# STM32G473 register map
File version: 2.2
CPU: CM4 r0p1, little endian, MPU, FPU, 4 interrupt priority bits
Registers are 32-bit, read-write, reset 0x0 unless marked. A register's access mark holds for its fields unless they carry their own. Offsets are from the block's base; [hi:lo] are bit positions; {n}, {i} and the like mark numbered series; 'fields as' and 'values as' point back to an identical list.

## TIM6 — Basic-timers
Base 0x40001000
Same registers: TIM7 0x40001400
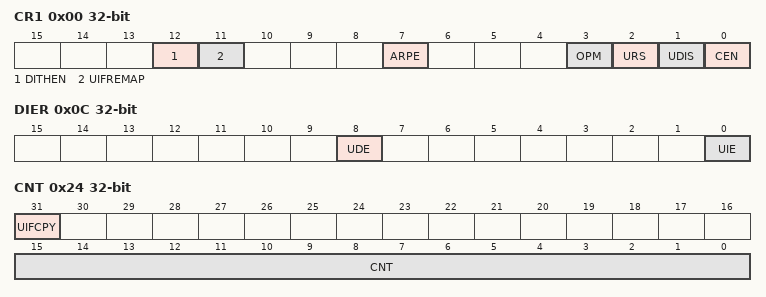
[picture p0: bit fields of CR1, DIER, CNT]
0x00 CR1 — control register 1
  [12] DITHEN — Dithering Enable
    0=Disabled (Dithering disabled); 1=Enabled (Dithering enabled)
  [11] UIFREMAP — UIF status bit remapping
    0=Disabled (No remapping. UIF status bit is not copied to TIMx_CNT register bit 31); 1=Enabled (Remapping enabled. UIF status bit is copied to TIMx_CNT register bit 31)
  [7] ARPE — Auto-reload preload enable
    0=Disabled (TIMx_APRR register is not buffered); 1=Enabled (TIMx_APRR register is buffered)
  [3] OPM — One-pulse mode
    0=Disabled (Counter is not stopped at update event); 1=Enabled (Counter stops counting at the next update event (clearing the CEN bit))
  [2] URS — Update request source
    0=AnyEvent (Any of counter overflow/underflow, setting UG, or update through slave mode, generates an update interrupt or DMA request); 1=CounterOnly (Only counter overflow/underflow generates an update interrupt or DMA request)
  [1] UDIS — Update disable
    0=Enabled (Update event enabled); 1=Disabled (Update event disabled)
  [0] CEN — Counter enable
    0=Disabled (Counter disabled); 1=Enabled (Counter enabled)
0x04 CR2 — control register 2
  [6:4] MMS — Master mode selection
    0=Reset (Use UG bit from TIMx_EGR register); 1=Enable (Use CNT bit from TIMx_CEN register); 2=Update (Use the update event)
0x0C DIER — DMA/Interrupt enable register
  [8] UDE — Update DMA request enable
    0=Disabled (Update DMA request disabled); 1=Enabled (Update DMA request enabled)
  [0] UIE — Update interrupt enable
    0=Disabled (Update interrupt disabled); 1=Enabled (Update interrupt enabled)
0x10 SR — status register
  [0] UIF write-0-clears — Update interrupt flag
    on read: 0=NoUpdateOccurred; 1=UpdatePending (Update interrupt pending) | on write: 0=Clear flag
0x14 EGR wo — event generation register
  [0] UG — Update generation
    1=Update (Re-initializes the timer counter and generates an update of the registers.)
0x24 CNT access per field — counter
  [31] UIFCPY ro — UIF Copy
    0=NoUpdateOccurred; 1=UpdatePending (Update interrupt pending)
  [15:0] CNT rw — Low counter value
0x28 PSC — prescaler
  [15:0] PSC — Prescaler value
0x2C ARR reset 0xFFFF — auto-reload register
  [19:0] ARR — Low Auto-reload value

## EXTI — External interrupt/event controller
Base 0x40010400
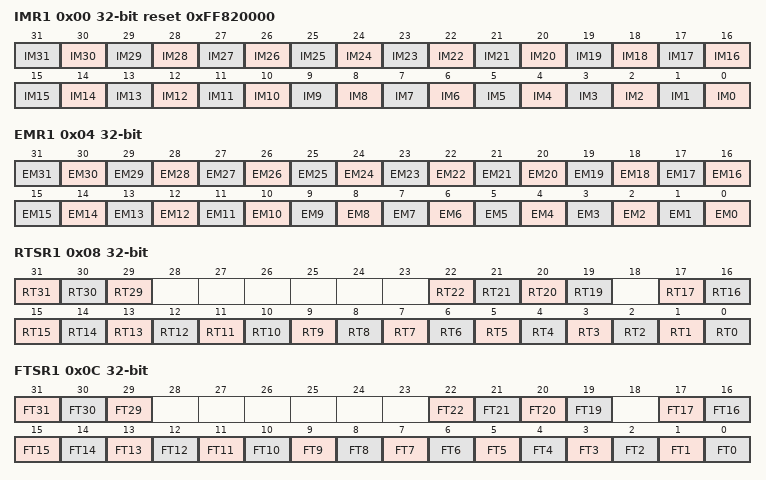
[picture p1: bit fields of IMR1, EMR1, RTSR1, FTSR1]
0x00 IMR1 reset 0xFF820000 — Interrupt mask register
  [all] fields
    0=Masked (Interrupt request line is masked); 1=Unmasked (Interrupt request line is unmasked)
  [n] IM{n} (n=0..31) — Interrupt Mask on line {n}
0x04 EMR1 — Event mask register
  [all] fields
    0=Masked (Event request line is masked); 1=Unmasked (Event request line is unmasked)
  [n] EM{n} (n=0..31) — Event Mask on line {n}
0x08 RTSR1 — Rising Trigger selection register
  [all] fields
    0=Disabled (Rising edge trigger is disabled); 1=Enabled (Rising edge trigger is enabled)
  [31] RT31 — Rising trigger event configuration of line 31
  [30] RT30 — Rising trigger event configuration of line 30
  [29] RT29 — Rising trigger event configuration of line 29
  [n] RT{n} (n=19..22) — Rising trigger event configuration of line {n}
  [n] RT{n} (n=0..17) — Rising trigger event configuration of line {n}
0x0C FTSR1 — Falling Trigger selection register
  [all] fields
    0=Disabled (Falling edge trigger is disabled); 1=Enabled (Falling edge trigger is enabled)
  [31] FT31 — Falling trigger event configuration of line 31
  [30] FT30 — Falling trigger event configuration of line 30
  [29] FT29 — Falling trigger event configuration of line 29
  [n] FT{n} (n=19..22) — Falling trigger event configuration of line {n}
  [n] FT{n} (n=0..17) — Falling trigger event configuration of line {n}
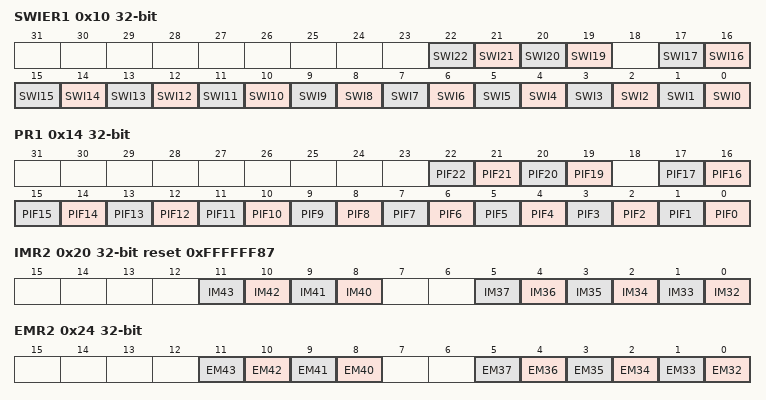
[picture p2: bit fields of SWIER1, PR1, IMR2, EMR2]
0x10 SWIER1 — Software interrupt event register
  [all] fields
    on write: 1=Pend (Generates an interrupt request)
  [n] SWI{n} (n=19..22) — Software Interrupt on line {n}
  [n] SWI{n} (n=0..17) — Software Interrupt on line {n}
0x14 PR1 — Pending register
  [all] fields
    on read: 0=NotPending (No trigger request occurred); 1=Pending (Selected trigger request occurred) | on write: 1=Clears pending bit
  [n] PIF{n} write-1-clears (n=19..22) — Pending bit {n}
  [n] PIF{n} write-1-clears (n=0..17) — Pending bit {n}
0x20 IMR2 reset 0xFFFFFF87 — Interrupt mask register
  [all] fields
    values as the fields of IMR1
  [n-32] IM{n} (n=40..43) — Interrupt Mask on external/internal line {n}
  [n-32] IM{n} (n=32..37) — Interrupt Mask on external/internal line {n}
0x24 EMR2 — Event mask register
  [all] fields
    values as the fields of EMR1
  [n-32] EM{n} (n=40..43) — Event mask on external/internal line {n}
  [n-32] EM{n} (n=32..37) — Event mask on external/internal line {n}
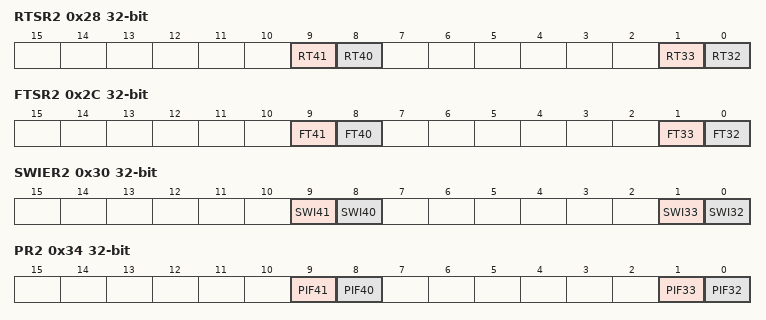
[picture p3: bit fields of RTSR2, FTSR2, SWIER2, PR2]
0x28 RTSR2 — Rising Trigger selection register
  [all] fields
    values as the fields of RTSR1
  [9] RT41 — Rising trigger event configuration bit of line 41
  [8] RT40 — Rising trigger event configuration bit of line 40
  [1] RT33 — Rising trigger event configuration bit of line 32
  [0] RT32 — Rising trigger event configuration bit of line 32
0x2C FTSR2 — Falling Trigger selection register
  [all] fields
    values as the fields of FTSR1
  [9] FT41 — Falling trigger event configuration of line 41
  [8] FT40 — Falling trigger event configuration of line 40
  [1] FT33 — Falling trigger event configuration of line 33
  [0] FT32 — Falling trigger event configuration of line 32
0x30 SWIER2 — Software interrupt event register
  [all] fields
    on write: 1=Pend (Generates an interrupt request)
  [9] SWI41 — Software interrupt on line 41
  [8] SWI40 — Software interrupt on line 40
  [1] SWI33 — Software interrupt on line 33
  [0] SWI32 — Software interrupt on line 32
0x34 PR2 — Pending register
  [all] fields
    values as the fields of PR1
  [9] PIF41 write-1-clears — Pending bit 41
  [8] PIF40 write-1-clears — Pending bit 40
  [1] PIF33 write-1-clears — Pending bit 33
  [0] PIF32 write-1-clears — Pending bit 32
